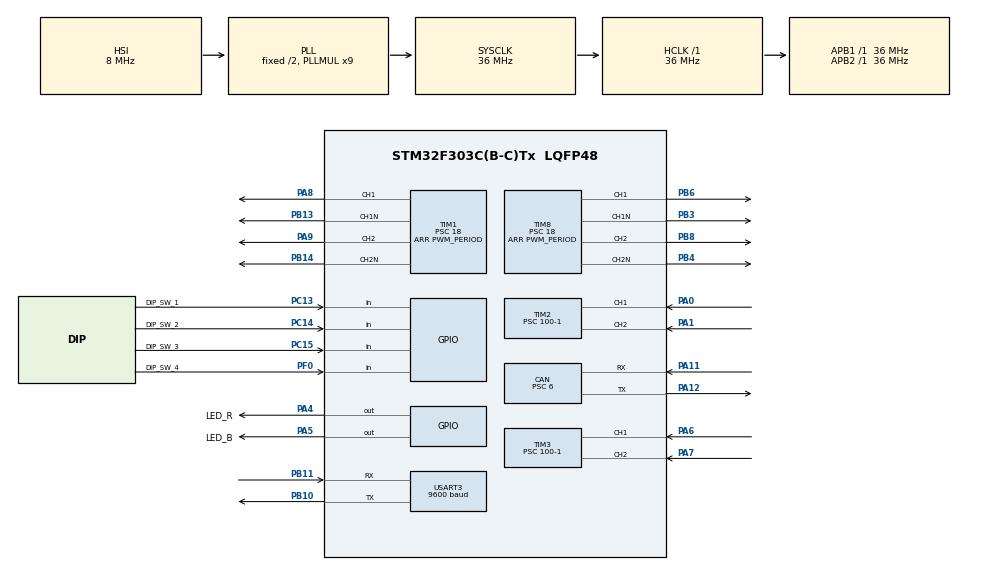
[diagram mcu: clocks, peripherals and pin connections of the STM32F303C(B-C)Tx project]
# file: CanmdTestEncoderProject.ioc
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CAN.ABOM=DISABLE
CAN.AWUM=DISABLE
CAN.BS1=CAN_BS1_3TQ
CAN.BS2=CAN_BS2_2TQ
CAN.CalculateTimeQuantum=166.66666666666669
CAN.Mode=CAN_MODE_NORMAL
CAN.NART=DISABLE
CAN.Prescaler=6
CAN.RFLM=DISABLE
CAN.SJW=CAN_SJW_1TQ
CAN.TTCM=DISABLE
CAN.TXFP=DISABLE
Mcu.Family=STM32F3
Mcu.Name=STM32F303C(B-C)Tx
Mcu.Package=LQFP48
Mcu.UserConstants=PWM_PERIOD,200;PWM_DUTY_ZERO,100;PWM_DUTY_MAX,95;MAX_ENCODER_COUNT,100
NVIC.PriorityGroup=NVIC_PRIORITYGROUP_4
NVIC.TIM2_IRQn=true\:5\:0\:true\:false\:true\:true\:true
NVIC.TIM3_IRQn=true\:4\:0\:true\:false\:true\:true\:true
NVIC.TIM6_DAC_IRQn=true\:6\:0\:true\:false\:true\:true\:true
NVIC.TIM7_IRQn=true\:1\:0\:true\:false\:true\:true\:true
NVIC.USB_LP_CAN_RX0_IRQn=true\:7\:0\:true\:false\:true\:true\:true
PA0.Signal=S_TIM2_CH1_ETR
PA1.Signal=S_TIM2_CH2
PA11.Mode=Master
PA11.Signal=CAN_RX
PA12.Mode=Master
PA12.Signal=CAN_TX
PA13.Mode=Serial_Wire
PA13.Signal=SYS_JTMS-SWDIO
PA14.Mode=Serial_Wire
PA14.Signal=SYS_JTCK-SWCLK
PA4.GPIO_Label=LED_R
PA4.PinState=GPIO_PIN_SET
PA4.Signal=GPIO_Output
PA5.GPIO_Label=LED_B
PA5.PinState=GPIO_PIN_SET
PA5.Signal=GPIO_Output
PA6.Signal=S_TIM3_CH1
PA7.Signal=S_TIM3_CH2
PA8.Signal=S_TIM1_CH1
PA9.Signal=S_TIM1_CH2
PB10.Mode=Asynchronous
PB10.Signal=USART3_TX
PB11.Mode=Asynchronous
PB11.Signal=USART3_RX
PB13.Mode=PWM Generation1 CH1 CH1N
PB13.Signal=TIM1_CH1N
PB14.Mode=PWM Generation2 CH2 CH2N
PB14.Signal=TIM1_CH2N
PB3.Mode=PWM Generation1 CH1 CH1N
PB3.Signal=TIM8_CH1N
PB4.Mode=PWM Generation2 CH2 CH2N
PB4.Signal=TIM8_CH2N
PB6.Signal=S_TIM8_CH1
PB8.Signal=S_TIM8_CH2
PC13.GPIO_Label=DIP_SW_1
PC13.GPIO_PuPd=GPIO_PULLUP
PC13.Signal=GPIO_Input
PC14-OSC32_IN.GPIO_Label=DIP_SW_2
PC14-OSC32_IN.GPIO_PuPd=GPIO_PULLUP
PC14-OSC32_IN.Signal=GPIO_Input
PC15-OSC32_OUT.GPIO_Label=DIP_SW_3
PC15-OSC32_OUT.GPIO_PuPd=GPIO_PULLUP
PC15-OSC32_OUT.Signal=GPIO_Input
PF0-OSC_IN.GPIO_Label=DIP_SW_4
PF0-OSC_IN.GPIO_PuPd=GPIO_PULLUP
PF0-OSC_IN.Signal=GPIO_Input
ProjectManager.HeapSize=0x200
ProjectManager.StackSize=0x400
ProjectManager.TargetToolchain=SW4STM32
RCC.AHBFreq_Value=36000000
RCC.APB1Freq_Value=36000000
RCC.APB1TimFreq_Value=36000000
RCC.APB2Freq_Value=36000000
RCC.APB2TimFreq_Value=36000000
RCC.CortexFreq_Value=36000000
RCC.FLatency=FLASH_LATENCY_1
RCC.HCLKFreq_Value=36000000
RCC.HSE_VALUE=8000000
RCC.HSI_VALUE=8000000
RCC.LSE_VALUE=32768
RCC.PLLMUL=RCC_PLL_MUL9
RCC.SYSCLKFreq_VALUE=36000000
RCC.SYSCLKSourceVirtual=RCC_SYSCLKSOURCE_PLLCLK
RCC.USBFreq_Value=36000000
SH.S_TIM1_CH1.0=TIM1_CH1,PWM Generation1 CH1 CH1N
SH.S_TIM1_CH2.0=TIM1_CH2,PWM Generation2 CH2 CH2N
SH.S_TIM2_CH1_ETR.0=TIM2_CH1,Encoder_Interface
SH.S_TIM2_CH2.0=TIM2_CH2,Encoder_Interface
SH.S_TIM3_CH1.0=TIM3_CH1,Encoder_Interface
SH.S_TIM3_CH2.0=TIM3_CH2,Encoder_Interface
SH.S_TIM8_CH1.0=TIM8_CH1,PWM Generation1 CH1 CH1N
SH.S_TIM8_CH2.0=TIM8_CH2,PWM Generation2 CH2 CH2N
TIM1.AutoReloadPreload=TIM_AUTORELOAD_PRELOAD_DISABLE
TIM1.AutomaticOutput=TIM_AUTOMATICOUTPUT_DISABLE
TIM1.Break2Filter=0
TIM1.Break2Polarity=TIM_BREAK2POLARITY_HIGH
TIM1.Break2State=TIM_BREAK2_DISABLE
TIM1.BreakFilter=0
TIM1.BreakPolarity=TIM_BREAKPOLARITY_HIGH
TIM1.BreakState=TIM_BREAK_DISABLE
TIM1.Channel-PWM\ Generation1\ CH1\ CH1N=TIM_CHANNEL_1
TIM1.Channel-PWM\ Generation2\ CH2\ CH2N=TIM_CHANNEL_2
TIM1.ClearInputSource=TIM_CLEARINPUTSOURCE_NONE
TIM1.ClockDivision=TIM_CLOCKDIVISION_DIV1
TIM1.CounterMode=TIM_COUNTERMODE_UP
TIM1.DeadTime=18
TIM1.LockLevel=TIM_LOCKLEVEL_OFF
TIM1.OCFastMode_PWM-PWM\ Generation1\ CH1\ CH1N=TIM_OCFAST_DISABLE
TIM1.OCFastMode_PWM-PWM\ Generation2\ CH2\ CH2N=TIM_OCFAST_DISABLE
TIM1.OCIdleState_1=TIM_OCIDLESTATE_RESET
TIM1.OCIdleState_2=TIM_OCIDLESTATE_RESET
TIM1.OCMode_PWM-PWM\ Generation1\ CH1\ CH1N=TIM_OCMODE_PWM1
TIM1.OCMode_PWM-PWM\ Generation2\ CH2\ CH2N=TIM_OCMODE_PWM1
TIM1.OCNIdleState_1=TIM_OCNIDLESTATE_RESET
TIM1.OCNIdleState_2=TIM_OCNIDLESTATE_RESET
TIM1.OCNPolarity_1=TIM_OCNPOLARITY_HIGH
TIM1.OCNPolarity_2=TIM_OCNPOLARITY_HIGH
TIM1.OCPolarity_1=TIM_OCPOLARITY_HIGH
TIM1.OCPolarity_2=TIM_OCPOLARITY_HIGH
TIM1.OffStateIDLEMode=TIM_OSSI_DISABLE
TIM1.OffStateRunMode=TIM_OSSR_DISABLE
TIM1.Period=PWM_PERIOD
TIM1.Prescaler=18
TIM1.Pulse-PWM\ Generation1\ CH1\ CH1N=PWM_DUTY_ZERO
TIM1.Pulse-PWM\ Generation2\ CH2\ CH2N=PWM_DUTY_ZERO
TIM1.RepetitionCounter=0
TIM1.TIM_MasterOutputTrigger=TIM_TRGO_RESET
TIM1.TIM_MasterOutputTrigger2=TIM_TRGO2_RESET
TIM1.TIM_MasterSlaveMode=TIM_MASTERSLAVEMODE_DISABLE
TIM2.AutoReloadPreload=TIM_AUTORELOAD_PRELOAD_DISABLE
TIM2.ClockDivision=TIM_CLOCKDIVISION_DIV1
TIM2.CounterMode=TIM_COUNTERMODE_UP
TIM2.EncoderMode=TIM_ENCODERMODE_TI12
TIM2.IC1Filter=0
TIM2.IC1Polarity=TIM_ICPOLARITY_RISING
TIM2.IC1Prescaler=TIM_ICPSC_DIV1
TIM2.IC1Selection=TIM_ICSELECTION_DIRECTTI
TIM2.IC2Filter=0
TIM2.IC2Polarity=TIM_ICPOLARITY_RISING
TIM2.IC2Prescaler=TIM_ICPSC_DIV1
TIM2.IC2Selection=TIM_ICSELECTION_DIRECTTI
TIM2.Period=MAX_ENCODER_COUNT
TIM2.Prescaler=100-1
TIM2.TIM_MasterOutputTrigger=TIM_TRGO_UPDATE
TIM2.TIM_MasterSlaveMode=TIM_MASTERSLAVEMODE_DISABLE
TIM3.AutoReloadPreload=TIM_AUTORELOAD_PRELOAD_DISABLE
TIM3.ClockDivision=TIM_CLOCKDIVISION_DIV1
TIM3.CounterMode=TIM_COUNTERMODE_UP
TIM3.EncoderMode=TIM_ENCODERMODE_TI12
TIM3.IC1Filter=0
TIM3.IC1Polarity=TIM_ICPOLARITY_RISING
TIM3.IC1Prescaler=TIM_ICPSC_DIV1
TIM3.IC1Selection=TIM_ICSELECTION_DIRECTTI
TIM3.IC2Filter=0
TIM3.IC2Polarity=TIM_ICPOLARITY_RISING
TIM3.IC2Prescaler=TIM_ICPSC_DIV1
TIM3.IC2Selection=TIM_ICSELECTION_DIRECTTI
TIM3.Period=MAX_ENCODER_COUNT
TIM3.Prescaler=100-1
TIM3.TIM_MasterOutputTrigger=TIM_TRGO_RESET
TIM3.TIM_MasterSlaveMode=TIM_MASTERSLAVEMODE_DISABLE
TIM6.AutoReloadPreload=TIM_AUTORELOAD_PRELOAD_DISABLE
TIM6.CounterMode=TIM_COUNTERMODE_UP
TIM6.Period=319
TIM6.Prescaler=1000
TIM6.TIM_MasterOutputTrigger=TIM_TRGO_RESET
TIM7.AutoReloadPreload=TIM_AUTORELOAD_PRELOAD_DISABLE
TIM7.CounterMode=TIM_COUNTERMODE_UP
TIM7.Period=3599
TIM7.Prescaler=1000
TIM7.TIM_MasterOutputTrigger=TIM_TRGO_RESET
TIM8.AutoReloadPreload=TIM_AUTORELOAD_PRELOAD_DISABLE
TIM8.AutomaticOutput=TIM_AUTOMATICOUTPUT_DISABLE
TIM8.Break2Filter=0
TIM8.Break2Polarity=TIM_BREAK2POLARITY_HIGH
TIM8.Break2State=TIM_BREAK2_DISABLE
TIM8.BreakFilter=0
TIM8.BreakPolarity=TIM_BREAKPOLARITY_HIGH
TIM8.BreakState=TIM_BREAK_DISABLE
TIM8.Channel-PWM\ Generation1\ CH1\ CH1N=TIM_CHANNEL_1
TIM8.Channel-PWM\ Generation2\ CH2\ CH2N=TIM_CHANNEL_2
TIM8.ClearInputSource=TIM_CLEARINPUTSOURCE_NONE
TIM8.ClockDivision=TIM_CLOCKDIVISION_DIV1
TIM8.CounterMode=TIM_COUNTERMODE_UP
TIM8.DeadTime=18
TIM8.LockLevel=TIM_LOCKLEVEL_OFF
TIM8.OCFastMode_PWM-PWM\ Generation1\ CH1\ CH1N=TIM_OCFAST_DISABLE
TIM8.OCFastMode_PWM-PWM\ Generation2\ CH2\ CH2N=TIM_OCFAST_DISABLE
TIM8.OCIdleState_1=TIM_OCIDLESTATE_RESET
TIM8.OCIdleState_2=TIM_OCIDLESTATE_RESET
TIM8.OCMode_PWM-PWM\ Generation1\ CH1\ CH1N=TIM_OCMODE_PWM1
TIM8.OCMode_PWM-PWM\ Generation2\ CH2\ CH2N=TIM_OCMODE_PWM1
TIM8.OCNIdleState_1=TIM_OCNIDLESTATE_RESET
TIM8.OCNIdleState_2=TIM_OCNIDLESTATE_RESET
TIM8.OCNPolarity_1=TIM_OCNPOLARITY_HIGH
TIM8.OCNPolarity_2=TIM_OCNPOLARITY_HIGH
TIM8.OCPolarity_1=TIM_OCPOLARITY_HIGH
TIM8.OCPolarity_2=TIM_OCPOLARITY_HIGH
TIM8.OffStateIDLEMode=TIM_OSSI_DISABLE
TIM8.OffStateRunMode=TIM_OSSR_DISABLE
TIM8.Period=PWM_PERIOD
TIM8.Prescaler=18
TIM8.Pulse-PWM\ Generation1\ CH1\ CH1N=PWM_DUTY_ZERO
TIM8.Pulse-PWM\ Generation2\ CH2\ CH2N=PWM_DUTY_ZERO
TIM8.RepetitionCounter=0
TIM8.TIM_MasterOutputTrigger=TIM_TRGO_RESET
TIM8.TIM_MasterOutputTrigger2=TIM_TRGO2_RESET
TIM8.TIM_MasterSlaveMode=TIM_MASTERSLAVEMODE_DISABLE
USART3.AutoBaudRateEnableParam=UART_ADVFEATURE_AUTOBAUDRATE_DISABLE
USART3.BaudRate=9600
USART3.DMADisableonRxErrorParam=ADVFEATURE_DMA_ENABLEONRXERROR
USART3.DataInvertParam=ADVFEATURE_DATAINV_DISABLE
USART3.MSBFirstParam=ADVFEATURE_MSBFIRST_DISABLE
USART3.Mode=MODE_TX_RX
USART3.OneBitSampling=UART_ONE_BIT_SAMPLE_DISABLE
USART3.OverSampling=UART_OVERSAMPLING_16
USART3.OverrunDisableParam=ADVFEATURE_OVERRUN_ENABLE
USART3.Parity=PARITY_NONE
USART3.RxPinLevelInvertParam=ADVFEATURE_RXINV_DISABLE
USART3.StopBits=STOPBITS_1
USART3.SwapParam=ADVFEATURE_SWAP_DISABLE
USART3.TxPinLevelInvertParam=ADVFEATURE_TXINV_DISABLE
USART3.VirtualMode-Asynchronous=VM_ASYNC
USART3.WordLength=WORDLENGTH_8B
VP_TIM6_VS_ClockSourceINT.Mode=Enable_Timer
VP_TIM7_VS_ClockSourceINT.Mode=Enable_Timer
board=custom

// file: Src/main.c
/* USER CODE BEGIN Header */
/**
  ******************************************************************************
  * @file           : main.c
  * @brief          : Main program body
  ******************************************************************************
  * @attention
  *
  * <h2><center>&copy; Copyright (c) 2019 STMicroelectronics.
  * All rights reserved.</center></h2>
  *
  * This software component is licensed by ST under BSD 3-Clause license,
  * the "License"; You may not use this file except in compliance with the
  * License. You may obtain a copy of the License at:
  *                        opensource.org/licenses/BSD-3-Clause
  *
  ******************************************************************************
  */
/* USER CODE END Header */

#include "main.h"
#include "can.h"
#include "tim.h"
#include "usart.h"
#include "gpio.h"

/* USER CODE BEGIN Includes */
#include "cppmain.hpp"
/* USER CODE END Includes */

void SystemClock_Config(void);

int main(void)
{

  /* MCU Configuration--------------------------------------------------------*/

  /* Reset of all peripherals, Initializes the Flash interface and the Systick. */
  HAL_Init();

  /* Configure the system clock */
  SystemClock_Config();

  /* Initialize all configured peripherals */
  MX_GPIO_Init();
  MX_TIM1_Init();
  MX_TIM8_Init();
  MX_TIM2_Init();
  MX_TIM3_Init();
  MX_TIM6_Init();
  MX_TIM7_Init();
  MX_USART3_UART_Init();
  MX_CAN_Init();
  /* USER CODE BEGIN 2 */
  setup();

  /* USER CODE END 2 */

  /* Infinite loop */
  /* USER CODE BEGIN WHILE */
  while (1)
  {
    loop();
    /* USER CODE END WHILE */

  }
}

void SystemClock_Config(void)
{
  RCC_OscInitTypeDef RCC_OscInitStruct = {0};
  RCC_ClkInitTypeDef RCC_ClkInitStruct = {0};
  RCC_PeriphCLKInitTypeDef PeriphClkInit = {0};

  /** Initializes the CPU, AHB and APB busses clocks
  */
  RCC_OscInitStruct.OscillatorType = RCC_OSCILLATORTYPE_HSI;
  RCC_OscInitStruct.HSIState = RCC_HSI_ON;
  RCC_OscInitStruct.HSICalibrationValue = RCC_HSICALIBRATION_DEFAULT;
  RCC_OscInitStruct.PLL.PLLState = RCC_PLL_ON;
  RCC_OscInitStruct.PLL.PLLSource = RCC_PLLSOURCE_HSI;
  RCC_OscInitStruct.PLL.PLLMUL = RCC_PLL_MUL9;
  if (HAL_RCC_OscConfig(&RCC_OscInitStruct) != HAL_OK)
  {
    Error_Handler();
  }
  /** Initializes the CPU, AHB and APB busses clocks
  */
  RCC_ClkInitStruct.ClockType = RCC_CLOCKTYPE_HCLK|RCC_CLOCKTYPE_SYSCLK
                              |RCC_CLOCKTYPE_PCLK1|RCC_CLOCKTYPE_PCLK2;
  RCC_ClkInitStruct.SYSCLKSource = RCC_SYSCLKSOURCE_PLLCLK;
  RCC_ClkInitStruct.AHBCLKDivider = RCC_SYSCLK_DIV1;
  RCC_ClkInitStruct.APB1CLKDivider = RCC_HCLK_DIV1;
  RCC_ClkInitStruct.APB2CLKDivider = RCC_HCLK_DIV1;

  if (HAL_RCC_ClockConfig(&RCC_ClkInitStruct, FLASH_LATENCY_1) != HAL_OK)
  {
    Error_Handler();
  }
  PeriphClkInit.PeriphClockSelection = RCC_PERIPHCLK_USART3|RCC_PERIPHCLK_TIM1
                              |RCC_PERIPHCLK_TIM8;
  PeriphClkInit.Usart3ClockSelection = RCC_USART3CLKSOURCE_PCLK1;
  PeriphClkInit.Tim1ClockSelection = RCC_TIM1CLK_HCLK;
  PeriphClkInit.Tim8ClockSelection = RCC_TIM8CLK_HCLK;
  if (HAL_RCCEx_PeriphCLKConfig(&PeriphClkInit) != HAL_OK)
  {
    Error_Handler();
  }
}

void Error_Handler(void)
{
}

/************************ (C) COPYRIGHT STMicroelectronics *****END OF FILE****/
